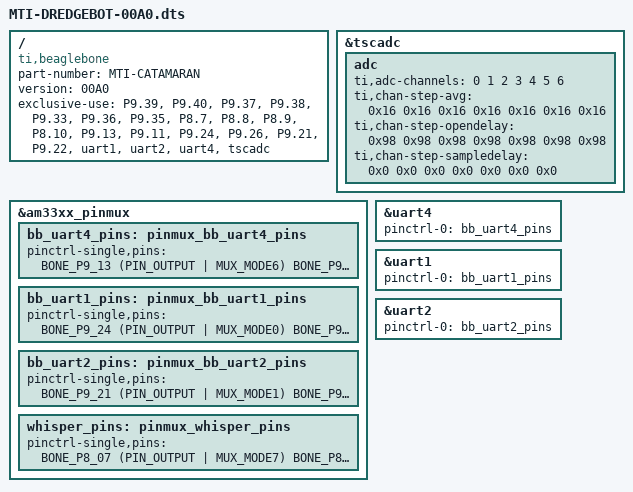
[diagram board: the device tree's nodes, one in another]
/*
 * Copyright (C) 2012 Texas Instruments Incorporated - http://www.ti.com/
 *
 * This program is free software; you can redistribute it and/or modify
 * it under the terms of the GNU General Public License version 2 as
 * published by the Free Software Foundation.
 */
/dts-v1/;
/plugin/;

/* 34xx mux mode options for each pin. See TRM for options */
#define MUX_MODE0	0
#define MUX_MODE1	1
#define MUX_MODE2	2
#define MUX_MODE3	3
#define MUX_MODE4	4
#define MUX_MODE5	5
#define MUX_MODE6	6
#define MUX_MODE7	7

/* 24xx/34xx mux bit defines */
#define PULL_ENA		(1 << 3)
#define PULL_UP			(1 << 4)
#define ALTELECTRICALSEL	(1 << 5)

/* omap3/4/5 specific mux bit defines */
#define INPUT_EN		(1 << 8)
#define OFF_EN			(1 << 9)
#define OFFOUT_EN		(1 << 10)
#define OFFOUT_VAL		(1 << 11)
#define OFF_PULL_EN		(1 << 12)
#define OFF_PULL_UP		(1 << 13)
#define WAKEUP_EN		(1 << 14)
#define WAKEUP_EVENT		(1 << 15)

/* Active pin states */
#define PIN_OUTPUT		0
#define PIN_OUTPUT_PULLUP	(PIN_OUTPUT | PULL_ENA | PULL_UP)
#define PIN_OUTPUT_PULLDOWN	(PIN_OUTPUT | PULL_ENA)
#define PIN_INPUT		INPUT_EN
#define PIN_INPUT_PULLUP	(PULL_ENA | INPUT_EN | PULL_UP)
#define PIN_INPUT_PULLDOWN	(PULL_ENA | INPUT_EN)

/* Off mode states */
#define PIN_OFF_NONE		0
#define PIN_OFF_OUTPUT_HIGH	(OFF_EN | OFFOUT_EN | OFFOUT_VAL)
#define PIN_OFF_OUTPUT_LOW	(OFF_EN | OFFOUT_EN)
#define PIN_OFF_INPUT_PULLUP	(OFF_EN | OFF_PULL_EN | OFF_PULL_UP)
#define PIN_OFF_INPUT_PULLDOWN	(OFF_EN | OFF_PULL_EN)
#define PIN_OFF_WAKEUPENABLE	WAKEUP_EN

/*
 * Macros to allow using the absolute physical address instead of the
 * padconf registers instead of the offset from padconf base.
 */
#define OMAP_IOPAD_OFFSET(pa, offset)	(((pa) & 0xffff) - (offset))

#define OMAP2420_CORE_IOPAD(pa, val)	OMAP_IOPAD_OFFSET((pa), 0x0030) (val)
#define OMAP2430_CORE_IOPAD(pa, val)	OMAP_IOPAD_OFFSET((pa), 0x2030) (val)
#define OMAP3_CORE1_IOPAD(pa, val)	OMAP_IOPAD_OFFSET((pa), 0x2030) (val)
#define OMAP3430_CORE2_IOPAD(pa, val)	OMAP_IOPAD_OFFSET((pa), 0x25d8) (val)
#define OMAP3630_CORE2_IOPAD(pa, val)	OMAP_IOPAD_OFFSET((pa), 0x25a0) (val)
#define OMAP3_WKUP_IOPAD(pa, val)	OMAP_IOPAD_OFFSET((pa), 0x2a00) (val)
#define DM816X_IOPAD(pa, val)		OMAP_IOPAD_OFFSET((pa), 0x0800) (val)
#define AM33XX_IOPAD(pa, val)		OMAP_IOPAD_OFFSET((pa), 0x0800) (val)
#define AM4372_IOPAD(pa, val)		OMAP_IOPAD_OFFSET((pa), 0x0800) (val)
#define DRA7XX_CORE_IOPAD(pa, val)	OMAP_IOPAD_OFFSET((pa), 0x3400) (val)

/*
 * Macros to allow using the offset from the padconf physical address
 * instead  of the offset from padconf base.
 */
#define OMAP_PADCONF_OFFSET(offset, base_offset)	((offset) - (base_offset))

#define OMAP4_IOPAD(offset, val)	OMAP_PADCONF_OFFSET((offset), 0x0040) (val)
#define OMAP5_IOPAD(offset, val)	OMAP_PADCONF_OFFSET((offset), 0x0040) (val)

/*
 * Define some commonly used pins configured by the boards.
 * Note that some boards use alternative pins, so check
 * the schematics before using these.
 */
#define OMAP3_UART1_RX		0x152
#define OMAP3_UART2_RX		0x14a
#define OMAP3_UART3_RX		0x16e
#define OMAP4_UART2_RX		0xdc
#define OMAP4_UART3_RX		0x104
#define OMAP4_UART4_RX		0x11c

#define GPIO_ACTIVE_HIGH 0
#define GPIO_ACTIVE_LOW 1

#define BONE_P8_03 0x018
#define BONE_P8_04 0x01C

#define BONE_P8_05 0x008
#define BONE_P8_06 0x00C
#define BONE_P8_07 0x090
#define BONE_P8_08 0x094

#define BONE_P8_09 0x09C
#define BONE_P8_10 0x098
#define BONE_P8_11 0x034
#define BONE_P8_12 0x030

#define BONE_P8_13 0x024
#define BONE_P8_14 0x028
#define BONE_P8_15 0x03C
#define BONE_P8_16 0x038

#define BONE_P8_17 0x02C
#define BONE_P8_18 0x08C
#define BONE_P8_19 0x020
#define BONE_P8_20 0x084

#define BONE_P8_21 0x080
#define BONE_P8_22 0x014
#define BONE_P8_23 0x010
#define BONE_P8_24 0x004

#define BONE_P8_25 0x000
#define BONE_P8_26 0x07C
#define BONE_P8_27 0x0E0
#define BONE_P8_28 0x0E8

#define BONE_P8_29 0x0E4
#define BONE_P8_30 0x0EC
#define BONE_P8_31 0x0D8
#define BONE_P8_32 0x0DC

#define BONE_P8_33 0x0D4
#define BONE_P8_34 0x0CC
#define BONE_P8_35 0x0D0
#define BONE_P8_36 0x0C8

#define BONE_P8_37 0x0C0
#define BONE_P8_38 0x0C4
#define BONE_P8_39 0x0B8
#define BONE_P8_40 0x0BC

#define BONE_P8_41 0x0B0
#define BONE_P8_42 0x0B4
#define BONE_P8_43 0x0A8
#define BONE_P8_44 0x0AC

#define BONE_P8_45 0x0A0
#define BONE_P8_46 0x0A4

#define BONE_P9_11 0x070
#define BONE_P9_12 0x078

#define BONE_P9_13 0x074
#define BONE_P9_14 0x048
#define BONE_P9_15 0x040
#define BONE_P9_16 0x04C

#define BONE_P9_17 0x15C
#define BONE_P9_18 0x158
#define BONE_P9_19 0x17C
#define BONE_P9_20 0x178

#define BONE_P9_21 0x154
#define BONE_P9_22 0x150
#define BONE_P9_23 0x044
#define BONE_P9_24 0x184

#define BONE_P9_25 0x1AC
#define BONE_P9_26 0x180
#define BONE_P9_27 0x1A4
#define BONE_P9_28 0x19C

#define BONE_P9_29 0x194
#define BONE_P9_30 0x198
#define BONE_P9_31 0x190

/* Shared P21 of P11 */
#define BONE_P9_41A 0x1B4
#define BONE_P9_41B 0x1A8

/* Shared P22 of P11 */
#define BONE_P9_42A 0x164
#define BONE_P9_42B 0x1A0

/* am33xx specific mux bit defines */
#define PULL_DISABLE		(1 << 3)
//#define INPUT_EN		(1 << 5)
#define SLEWCTRL_SLOW		(1 << 6)
#define SLEWCTRL_FAST		0

/* update macro depending on INPUT_EN and PULL_ENA */
#undef PIN_OUTPUT
#undef PIN_OUTPUT_PULLUP
#undef PIN_OUTPUT_PULLDOWN
#undef PIN_INPUT
#undef PIN_INPUT_PULLUP
#undef PIN_INPUT_PULLDOWN

#define PIN_OUTPUT		(PULL_DISABLE)
#define PIN_OUTPUT_PULLUP	(PULL_UP)
#define PIN_OUTPUT_PULLDOWN	0
#define PIN_INPUT		(INPUT_EN | PULL_DISABLE)
#define PIN_INPUT_PULLUP	(INPUT_EN | PULL_UP)
#define PIN_INPUT_PULLDOWN	(INPUT_EN)

/* undef non-existing modes */
#undef PIN_OFF_NONE
#undef PIN_OFF_OUTPUT_HIGH
#undef PIN_OFF_OUTPUT_LOW
#undef PIN_OFF_INPUT_PULLUP
#undef PIN_OFF_INPUT_PULLDOWN
#undef PIN_OFF_WAKEUPENABLE

/ {
	compatible = "ti,beaglebone", "ti,beaglebone-black", "ti,beaglebone-green";

	// identification
	part-number = "MTI-CATAMARAN";
	version = "00A0";

	// resources this cape uses
	exclusive-use =
    "P9.39",		// AIN0
    "P9.40",		// AIN1
    "P9.37",		// AIN2
    "P9.38",		// AIN3
    "P9.33",		// AIN4
    "P9.36",		// AIN5
    "P9.35",		// AIN6
    "P8.7",         // Whisper engine SB Step
    "P8.8",         // Whisper engine SB Dir
    "P8.9",         // Whisper engine PS Step
    "P8.10",        // Whisper engine PS Dir
    "P9.13",        // uart4_txd
    "P9.11",        // uart4_rxd
    "P9.24",		// uart1_txd
    "P9.26",		// uart1_rxd
    "P9.21",		// uart2_txd
    "P9.22",		// uart2_rxd

    "uart1",        // GPS Unit
    "uart2",        // Sonar controller
    "uart4",        // Razor IMU
    "tscadc";	    // Available

	fragment@0 {
		target = <&tscadc>;
		__overlay__ {

			status = "okay";
			adc {
				ti,adc-channels = <0 1 2 3 4 5 6>;
				ti,chan-step-avg = <0x16 0x16 0x16 0x16 0x16 0x16 0x16>;
				ti,chan-step-opendelay = <0x98 0x98 0x98 0x98 0x98 0x98 0x98>;
				ti,chan-step-sampledelay = <0x0 0x0 0x0 0x0 0x0 0x0 0x0>;
			};
		};
    };

    fragment@1 {
        target = <&am33xx_pinmux>;
        __overlay__ {
            bb_uart4_pins: pinmux_bb_uart4_pins {
                pinctrl-single,pins = <
                    BONE_P9_13 (PIN_OUTPUT | MUX_MODE6)	// gpmc_wpn.uart4_txd_mux2
                    BONE_P9_11 (PIN_INPUT  | MUX_MODE6)	// gpmc_wait0.uart4_rxd_mux2
                >;
            };
        };
    };

    fragment@2 {
        target = <&uart4>;
            __overlay__ {
                status = "okay";
                pinctrl-names = "default";
                pinctrl-0 = <&bb_uart4_pins>;
        };
    };

    fragment@3 {
        target = <&am33xx_pinmux>;
        __overlay__ {
            bb_uart1_pins: pinmux_bb_uart1_pins {
                pinctrl-single,pins = <
                BONE_P9_24 (PIN_OUTPUT | MUX_MODE0)	// uart1_txd.uart1_txd
                BONE_P9_26 (PIN_INPUT | MUX_MODE0)	// uart1_rxd.uart1_rxd
                >;
            };
        };
    };

    fragment@4 {
        target = <&uart1>;
            __overlay__ {
                status = "okay";
                pinctrl-names = "default";
                pinctrl-0 = <&bb_uart1_pins>;
        };
    };

    fragment@5 {
        target = <&am33xx_pinmux>;
        __overlay__ {
            bb_uart2_pins: pinmux_bb_uart2_pins {
                pinctrl-single,pins = <
                BONE_P9_21 (PIN_OUTPUT | MUX_MODE1)	// spi0_d0.uart2_txd
                BONE_P9_22 (PIN_INPUT  | MUX_MODE1)	// spi0_sclk.uart2_rxd
                >;
            };
        };
    };

    fragment@6 {
        target = <&uart2>;
            __overlay__ {
                status = "okay";
                pinctrl-names = "default";
                pinctrl-0 = <&bb_uart2_pins>;
        };
    };

    fragment@7 {
        target = <&am33xx_pinmux>;
        __overlay__ {
            whisper_pins: pinmux_whisper_pins {
                pinctrl-single,pins = <
                BONE_P8_07 (PIN_OUTPUT | MUX_MODE7)   // Whisper engine SB Step
                BONE_P8_08 (PIN_OUTPUT | MUX_MODE7)   // Whisper engine SB Dir
                BONE_P8_09 (PIN_OUTPUT | MUX_MODE7)   // Whisper engine PS Step
                BONE_P8_10 (PIN_OUTPUT | MUX_MODE7)   // Whisper engine PS Dir
                >;
            };
        };
    };


};
